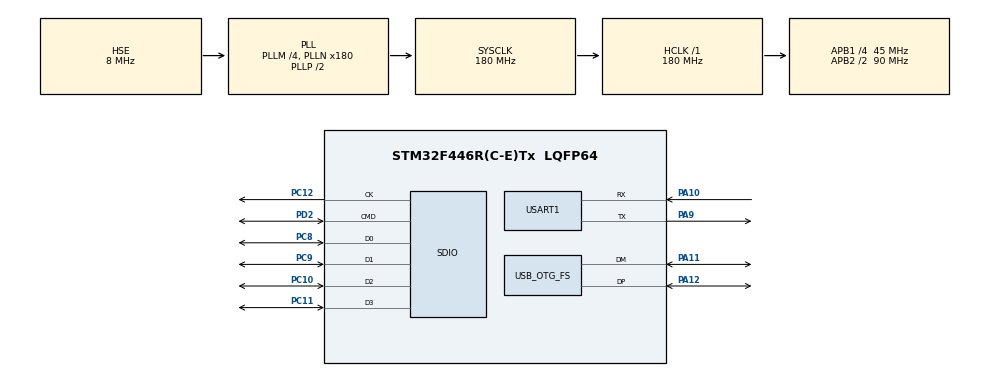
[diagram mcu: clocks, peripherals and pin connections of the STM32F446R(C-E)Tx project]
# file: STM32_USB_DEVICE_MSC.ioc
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Mcu.Family=STM32F4
Mcu.Name=STM32F446R(C-E)Tx
Mcu.Package=LQFP64
NVIC.OTG_FS_IRQn=true\:0\:0\:false\:false\:true\:false\:true\:true
NVIC.PriorityGroup=NVIC_PRIORITYGROUP_4
PA10.Mode=Asynchronous
PA10.Signal=USART1_RX
PA11.Mode=Device_Only
PA11.Signal=USB_OTG_FS_DM
PA12.Mode=Device_Only
PA12.Signal=USB_OTG_FS_DP
PA13.Mode=Serial_Wire
PA13.Signal=SYS_JTMS-SWDIO
PA14.Mode=Serial_Wire
PA14.Signal=SYS_JTCK-SWCLK
PA9.Mode=Asynchronous
PA9.Signal=USART1_TX
PC10.Mode=SD_4_bits_Wide_bus
PC10.Signal=SDIO_D2
PC11.Mode=SD_4_bits_Wide_bus
PC11.Signal=SDIO_D3
PC12.Mode=SD_4_bits_Wide_bus
PC12.Signal=SDIO_CK
PC8.Mode=SD_4_bits_Wide_bus
PC8.Signal=SDIO_D0
PC9.Mode=SD_4_bits_Wide_bus
PC9.Signal=SDIO_D1
PD2.Mode=SD_4_bits_Wide_bus
PD2.Signal=SDIO_CMD
PH0-OSC_IN.Mode=HSE-External-Oscillator
PH0-OSC_IN.Signal=RCC_OSC_IN
PH1-OSC_OUT.Mode=HSE-External-Oscillator
PH1-OSC_OUT.Signal=RCC_OSC_OUT
ProjectManager.HeapSize=0x200
ProjectManager.StackSize=0x400
ProjectManager.TargetToolchain=STM32CubeIDE
RCC.AHBFreq_Value=180000000
RCC.APB1CLKDivider=RCC_HCLK_DIV4
RCC.APB1Freq_Value=45000000
RCC.APB1TimFreq_Value=90000000
RCC.APB2CLKDivider=RCC_HCLK_DIV2
RCC.APB2Freq_Value=90000000
RCC.APB2TimFreq_Value=180000000
RCC.CortexFreq_Value=180000000
RCC.HCLKFreq_Value=180000000
RCC.HSE_VALUE=8000000
RCC.PLLM=4
RCC.PLLN=180
RCC.PLLSAIM=8
RCC.PLLSAIP=RCC_PLLSAIP_DIV4
RCC.PLLSourceVirtual=RCC_PLLSOURCE_HSE
RCC.SYSCLKFreq_VALUE=180000000
RCC.SYSCLKSource=RCC_SYSCLKSOURCE_PLLCLK
RCC.USBCLockSelection=RCC_CLK48CLKSOURCE_PLLSAIP
RCC.USBFreq_Value=48000000
RCC.VCOOutputFreq_Value=360000000
SDIO.ClockDiv=0
SDIO.HardwareFlowControl=SDIO_HARDWARE_FLOW_CONTROL_ENABLE
USART1.VirtualMode=VM_ASYNC
USB_DEVICE.CLASS_NAME_FS=MSC
USB_DEVICE.VirtualMode-MSC_FS=Msc
USB_DEVICE.VirtualModeFS=Msc_FS
USB_OTG_FS.VirtualMode=Device_Only
VP_USB_DEVICE_VS_USB_DEVICE_MSC_FS.Mode=MSC_FS
board=custom

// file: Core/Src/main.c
/* USER CODE BEGIN Header */
/**
  ******************************************************************************
  * @file           : main.c
  * @brief          : Main program body
  ******************************************************************************
  * @attention
  *
  * Copyright (c) 2026 STMicroelectronics.
  * All rights reserved.
  *
  * This software is licensed under terms that can be found in the LICENSE file
  * in the root directory of this software component.
  * If no LICENSE file comes with this software, it is provided AS-IS.
  *
  ******************************************************************************
  */
/* USER CODE END Header */
#include "main.h"
#include "usb_device.h"

/* USER CODE BEGIN Includes */
#include "stdio.h"
/* USER CODE END Includes */

SD_HandleTypeDef hsd;

UART_HandleTypeDef huart1;

void SystemClock_Config(void);
void PeriphCommonClock_Config(void);
static void MX_GPIO_Init(void);
static void MX_USART1_UART_Init(void);
static void MX_SDIO_SD_Init(void);

/* USER CODE BEGIN 0 */

int _write(int fd, unsigned char *buf, int len) {
  if (fd == 1 || fd == 2) {                     // stdout or stderr ?
    HAL_UART_Transmit(&huart1, buf, len, 999);  // Print to the UART
  }
  return len;
}

/* USER CODE END 0 */

int main(void)
{

  /* MCU Configuration--------------------------------------------------------*/

  /* Reset of all peripherals, Initializes the Flash interface and the Systick. */
  HAL_Init();

  /* Configure the system clock */
  SystemClock_Config();

  /* Configure the peripherals common clocks */
  PeriphCommonClock_Config();

  /* Initialize all configured peripherals */
  MX_GPIO_Init();
  MX_USART1_UART_Init();
  MX_USB_DEVICE_Init();
  MX_SDIO_SD_Init();

  /* Infinite loop */
  while (1)
  {

  }
}

void SystemClock_Config(void)
{
  RCC_OscInitTypeDef RCC_OscInitStruct = {0};
  RCC_ClkInitTypeDef RCC_ClkInitStruct = {0};

  /** Configure the main internal regulator output voltage
  */
  __HAL_RCC_PWR_CLK_ENABLE();
  __HAL_PWR_VOLTAGESCALING_CONFIG(PWR_REGULATOR_VOLTAGE_SCALE1);

  /** Initializes the RCC Oscillators according to the specified parameters
  * in the RCC_OscInitTypeDef structure.
  */
  RCC_OscInitStruct.OscillatorType = RCC_OSCILLATORTYPE_HSE;
  RCC_OscInitStruct.HSEState = RCC_HSE_ON;
  RCC_OscInitStruct.PLL.PLLState = RCC_PLL_ON;
  RCC_OscInitStruct.PLL.PLLSource = RCC_PLLSOURCE_HSE;
  RCC_OscInitStruct.PLL.PLLM = 4;
  RCC_OscInitStruct.PLL.PLLN = 180;
  RCC_OscInitStruct.PLL.PLLP = RCC_PLLP_DIV2;
  RCC_OscInitStruct.PLL.PLLQ = 2;
  RCC_OscInitStruct.PLL.PLLR = 2;
  if (HAL_RCC_OscConfig(&RCC_OscInitStruct) != HAL_OK)
  {
    Error_Handler();
  }

  /** Activate the Over-Drive mode
  */
  if (HAL_PWREx_EnableOverDrive() != HAL_OK)
  {
    Error_Handler();
  }

  /** Initializes the CPU, AHB and APB buses clocks
  */
  RCC_ClkInitStruct.ClockType = RCC_CLOCKTYPE_HCLK|RCC_CLOCKTYPE_SYSCLK
                              |RCC_CLOCKTYPE_PCLK1|RCC_CLOCKTYPE_PCLK2;
  RCC_ClkInitStruct.SYSCLKSource = RCC_SYSCLKSOURCE_PLLCLK;
  RCC_ClkInitStruct.AHBCLKDivider = RCC_SYSCLK_DIV1;
  RCC_ClkInitStruct.APB1CLKDivider = RCC_HCLK_DIV4;
  RCC_ClkInitStruct.APB2CLKDivider = RCC_HCLK_DIV2;

  if (HAL_RCC_ClockConfig(&RCC_ClkInitStruct, FLASH_LATENCY_5) != HAL_OK)
  {
    Error_Handler();
  }
}

void PeriphCommonClock_Config(void)
{
  RCC_PeriphCLKInitTypeDef PeriphClkInitStruct = {0};

  /** Initializes the peripherals clock
  */
  PeriphClkInitStruct.PeriphClockSelection = RCC_PERIPHCLK_SDIO|RCC_PERIPHCLK_CLK48;
  PeriphClkInitStruct.PLLSAI.PLLSAIM = 8;
  PeriphClkInitStruct.PLLSAI.PLLSAIN = 192;
  PeriphClkInitStruct.PLLSAI.PLLSAIQ = 2;
  PeriphClkInitStruct.PLLSAI.PLLSAIP = RCC_PLLSAIP_DIV4;
  PeriphClkInitStruct.PLLSAIDivQ = 1;
  PeriphClkInitStruct.Clk48ClockSelection = RCC_CLK48CLKSOURCE_PLLSAIP;
  PeriphClkInitStruct.SdioClockSelection = RCC_SDIOCLKSOURCE_CLK48;
  if (HAL_RCCEx_PeriphCLKConfig(&PeriphClkInitStruct) != HAL_OK)
  {
    Error_Handler();
  }
}

static void MX_SDIO_SD_Init(void)
{

  hsd.Instance = SDIO;
  hsd.Init.ClockEdge = SDIO_CLOCK_EDGE_RISING;
  hsd.Init.ClockBypass = SDIO_CLOCK_BYPASS_DISABLE;
  hsd.Init.ClockPowerSave = SDIO_CLOCK_POWER_SAVE_DISABLE;
  hsd.Init.BusWide = SDIO_BUS_WIDE_1B;
  hsd.Init.HardwareFlowControl = SDIO_HARDWARE_FLOW_CONTROL_ENABLE;
  hsd.Init.ClockDiv = 0;
  if (HAL_SD_Init(&hsd) != HAL_OK)
  {
    Error_Handler();
  }
  if (HAL_SD_ConfigWideBusOperation(&hsd, SDIO_BUS_WIDE_4B) != HAL_OK)
  {
    Error_Handler();
  }

}

static void MX_USART1_UART_Init(void)
{

  huart1.Instance = USART1;
  huart1.Init.BaudRate = 115200;
  huart1.Init.WordLength = UART_WORDLENGTH_8B;
  huart1.Init.StopBits = UART_STOPBITS_1;
  huart1.Init.Parity = UART_PARITY_NONE;
  huart1.Init.Mode = UART_MODE_TX_RX;
  huart1.Init.HwFlowCtl = UART_HWCONTROL_NONE;
  huart1.Init.OverSampling = UART_OVERSAMPLING_16;
  if (HAL_UART_Init(&huart1) != HAL_OK)
  {
    Error_Handler();
  }

}

static void MX_GPIO_Init(void)
{

  /* GPIO Ports Clock Enable */
  __HAL_RCC_GPIOH_CLK_ENABLE();
  __HAL_RCC_GPIOC_CLK_ENABLE();
  __HAL_RCC_GPIOA_CLK_ENABLE();
  __HAL_RCC_GPIOD_CLK_ENABLE();

}

void Error_Handler(void)
{
  __disable_irq();
  while (1)
  {
  }
}
